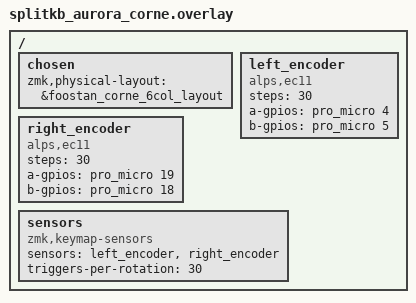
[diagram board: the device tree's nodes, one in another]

/{
  chosen {
    zmk,physical-layout = &foostan_corne_6col_layout;
  };

  left_encoder: left_encoder {
      compatible = "alps,ec11";
      steps = <80>;
      status = "disabled";

      a-gpios = <&pro_micro 4 GPIO_PULL_UP>;
      b-gpios = <&pro_micro 5 GPIO_PULL_UP>;
  };

  right_encoder: right_encoder {
      compatible = "alps,ec11";
      steps = <80>;
      status = "disabled";

      a-gpios = <&pro_micro 19 GPIO_PULL_UP>;
      b-gpios = <&pro_micro 18 GPIO_PULL_UP>;
  };

  sensors: sensors {
      compatible = "zmk,keymap-sensors";
      sensors = <&left_encoder &right_encoder>;
      triggers-per-rotation = <30>;
  };
};

&left_encoder { 
  steps = <30>;
  status = "okay";
};

&right_encoder {
  steps = <30>;
  status = "okay";
};

